VERSION "RSA observer 0.1"

CM_ "Signal layout reference: mlm92moo/openpilot 05dda21db2e055ba745e25705be02ab5ff848986, opendbc/toyota_nodsu_pt_generated.dbc. Diagnostic observations only.";
CM_ "SPDVAL1 units depend on TSGN1. Flags and supplementary signs are logged without assuming control eligibility. No checksum/counter signal is defined in this reference.";

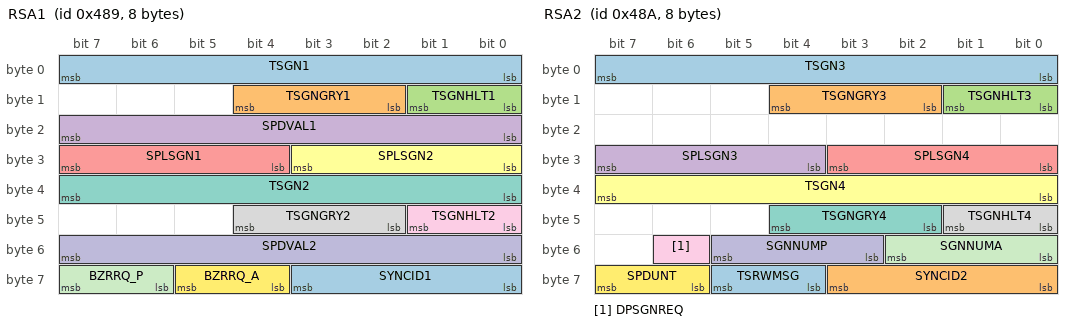
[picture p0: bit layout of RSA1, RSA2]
BO_ 1161 RSA1: 8 FCM
 SG_ TSGN1 : 7|8@0+ (1,0) [0|255] "" XXX
 SG_ TSGNGRY1 : 12|3@0+ (1,0) [0|7] "" XXX
 SG_ TSGNHLT1 : 9|2@0+ (1,0) [0|3] "" XXX
 SG_ SPDVAL1 : 23|8@0+ (1,0) [0|255] "" XXX
 SG_ SPLSGN1 : 31|4@0+ (1,0) [0|15] "" XXX
 SG_ SPLSGN2 : 27|4@0+ (1,0) [0|15] "" XXX
 SG_ TSGN2 : 39|8@0+ (1,0) [0|255] "" XXX
 SG_ TSGNGRY2 : 44|3@0+ (1,0) [0|7] "" XXX
 SG_ TSGNHLT2 : 41|2@0+ (1,0) [0|3] "" XXX
 SG_ SPDVAL2 : 55|8@0+ (1,0) [0|255] "" XXX
 SG_ BZRRQ_P : 63|2@0+ (1,0) [0|3] "" XXX
 SG_ BZRRQ_A : 61|2@0+ (1,0) [0|3] "" XXX
 SG_ SYNCID1 : 59|4@0+ (1,0) [0|15] "" XXX

BO_ 1162 RSA2: 8 FCM
 SG_ TSGN3 : 7|8@0+ (1,0) [0|255] "" XXX
 SG_ TSGNGRY3 : 12|3@0+ (1,0) [0|7] "" XXX
 SG_ TSGNHLT3 : 9|2@0+ (1,0) [0|3] "" XXX
 SG_ SPLSGN3 : 31|4@0+ (1,0) [0|15] "" XXX
 SG_ SPLSGN4 : 27|4@0+ (1,0) [0|15] "" XXX
 SG_ TSGN4 : 39|8@0+ (1,0) [0|255] "" XXX
 SG_ TSGNGRY4 : 44|3@0+ (1,0) [0|7] "" XXX
 SG_ TSGNHLT4 : 41|2@0+ (1,0) [0|3] "" XXX
 SG_ DPSGNREQ : 54|1@0+ (1,0) [0|1] "" XXX
 SG_ SGNNUMP : 53|3@0+ (1,0) [0|7] "" XXX
 SG_ SGNNUMA : 50|3@0+ (1,0) [0|7] "" XXX
 SG_ SPDUNT : 63|2@0+ (1,0) [0|3] "" XXX
 SG_ TSRWMSG : 61|2@0+ (1,0) [0|3] "" XXX
 SG_ SYNCID2 : 59|4@0+ (1,0) [0|15] "" XXX
